# SKEAZN84 register map
Vendor: Freescale Semiconductor, Inc.; Series: Kinetis_EA; File version: 1.6
CPU: CM0PLUS r0p0, little endian, no MPU, no FPU, VTOR, 2 interrupt priority bits
Registers are 32-bit, read-write, reset 0x0 unless marked. A register's access mark holds for its fields unless they carry their own. Offsets are from the block's base; [hi:lo] are bit positions; {n}, {i} and the like mark numbered series; 'fields as' and 'values as' point back to an identical list.

## PORT — Port control and interrupts
Base 0x40049000; register names take the prefix PORT_
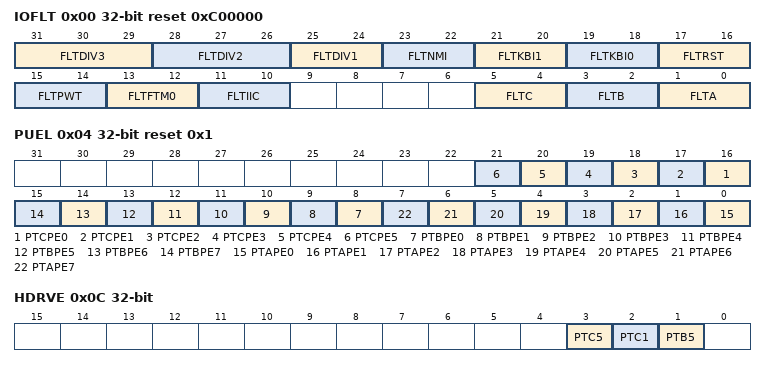
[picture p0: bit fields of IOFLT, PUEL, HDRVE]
0x00 IOFLT reset 0xC00000 — Port Filter Register
  [31:29] FLTDIV3 — Filter Division Set 3
    0=LPOCLK; 1=LPOCLK/2; 2=LPOCLK/4; 3=LPOCLK/8; 4=LPOCLK/16; 5=LPOCLK/32; 6=LPOCLK/64; 7=LPOCLK/128
  [28:26] FLTDIV2 — Filter Division Set 2
    0=BUSCLK/32; 1=BUSCLK/64; 2=BUSCLK/128; 3=BUSCLK/256; 4=BUSCLK/512; 5=BUSCLK/1024; 6=BUSCLK/2048; 7=BUSCLK/4096
  [25:24] FLTDIV1 — Filter Division Set 1
    0=BUSCLK/2; 1=BUSCLK/4; 2=BUSCLK/8; 3=BUSCLK/16
  [23:22] FLTNMI — Filter Selection for Input from NMI
    0=No filter; 1=Selects FLTDIV1, and will switch to FLTDIV3 in Stop mode automatically; 2=Selects FLTDIV2, and will switch to FLTDIV3 in Stop mode automatically; 3=FLTDIV3
  [21:20] FLTKBI1 — Filter Selection for Input from KBI1
    values as FLTNMI
  [19:18] FLTKBI0 — Filter selection for Input from KBI0
    values as FLTNMI
  [17:16] FLTRST — Filter Selection for Input from RESET/IRQ
    values as FLTNMI
  [15:14] FLTPWT — Filter Selection For Input from PWT_IN1/PWT_IN0
    0=No filter; 1=Select FLTDIV1; 2=Select FLTDIV2; 3=Select FLTDIV3
  [13:12] FLTFTM0 — Filter Selection For Input from FTM0CH0/FTM0CH1
    values as FLTPWT
  [11:10] FLTIIC — Filter Selection For Input from SCL/SDA
    0=No filter; 1=Select FLTDIV1; 2=Select FLTDIV2; 3=Select BUSCLK
  [5:4] FLTC — Filter Selection for Input from PTC
    0=BUSCLK; 1=FLTDIV1; 2=FLTDIV2; 3=FLTDIV3
  [3:2] FLTB — Filter Selection for Input from PTB
    0=BUSCLK; 1=FLTDIV1; 2=FLTDIV2; 3=FLTDIV3
  [1:0] FLTA — Filter Selection for Input from PTA
    0=BUSCLK; 1=FLTDIV1; 2=FLTDIV2; 3=FLTDIV3
0x04 PUEL reset 0x1 — Port Pullup Enable Low Register
  [n+16] PTCPE{n} (n=0..5) — Pull Enable for Port C Bit {n}
    0=Pullup is disabled for port C bit {n}; 1=Pullup is enabled for port C bit {n}
  [n+8] PTBPE{n} (n=0..7) — Pull Enable for Port B Bit {n}
    0=Pullup is disabled for port B bit {n}; 1=Pullup is enabled for port B bit {n}
  [n] PTAPE{n} (n=0..7) — Pull Enable for Port A Bit {n}
    0=Pullup is disabled for port A bit {n}; 1=Pullup is enabled for port A bit {n}
0x0C HDRVE — Port High Drive Enable Register
  [3] PTC5 — High Current Drive Capability of PTC5
    0=PTC5 is disabled to offer high current drive capability; 1=PTC5 is enabled to offer high current drive capability
  [2] PTC1 — High Current Drive Capability of PTC1
    0=PTC1 is disabled to offer high current drive capability; 1=PTC1 is enabled to offer high current drive capability
  [1] PTB5 — High Current Drive Capability of PTB5
    0=PTB5 is disabled to offer high current drive capability; 1=PTB5 is enabled to offer high current drive capability

## WDOG — Watchdog timer
Base 0x40052000; register names take the prefix WDOG_
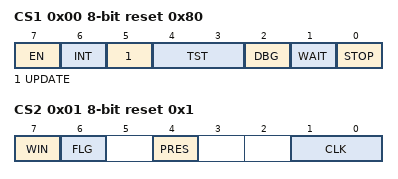
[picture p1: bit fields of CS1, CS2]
0x00 CS1 8-bit reset 0x80 — Watchdog Control and Status Register 1
  [7] EN — Watchdog Enable
    0=Watchdog disabled; 1=Watchdog enabled
  [6] INT — Watchdog Interrupt
    0=Watchdog interrupts are disabled. Watchdog resets are not delayed.; 1=Watchdog interrupts are enabled. Watchdog resets are delayed by 128 bus clocks.
  [5] UPDATE — Allow updates
    0=Updates not allowed. After the initial configuration, the watchdog cannot be later modified without forcing a reset.; 1=Updates allowed. Software can modify the watchdog configuration registers within 128 bus clocks after performing the unlock write sequence.
  [4:3] TST — Watchdog Test
    0=Watchdog test mode disabled; 1=Watchdog user mode enabled. (Watchdog test mode disabled.) After testing the watchdog, software should use this setting to indicate that the watchdog is functioning normally in user mode.; 2=Watchdog test mode enabled, only the low byte is used. WDOG_CNTL is compared with WDOG_TOVALL.; 3=Watchdog test mode enabled, only the high byte is used. WDOG_CNTH is compared with WDOG_TOVALH.
  [2] DBG — Debug Enable
    0=Watchdog disabled in chip debug mode; 1=Watchdog enabled in chip debug mode
  [1] WAIT — Wait Enable
    0=Watchdog disabled in chip wait mode; 1=Watchdog enabled in chip wait mode
  [0] STOP — Stop Enable
    0=Watchdog disabled in chip stop mode; 1=Watchdog enabled in chip stop mode
0x01 CS2 8-bit reset 0x1 — Watchdog Control and Status Register 2
  [7] WIN — Watchdog Window
    0=Window mode disabled; 1=Window mode enabled
  [6] FLG — Watchdog Interrupt Flag
    0=No interrupt occurred; 1=An interrupt occurred
  [4] PRES — Watchdog Prescalar
    0=256 prescalar disabled; 1=256 prescalar enabled
  [1:0] CLK — Watchdog Clock
    0=Bus clock; 1=1 kHz internal low-power oscillator (LPOCLK); 2=32 kHz internal oscillator (ICSIRCLK); 3=External clock source
0x02 CNT 16-bit (WDOG view) — Watchdog Counter Register.
  [15:0] CNT — Watchdog Counter Value
0x02 CNTH 8-bit ro (WDOG view) — Watchdog Counter Register: High
  [7:0] CNTHIGH — High byte of the Watchdog Counter
0x03 CNTL 8-bit ro — Watchdog Counter Register: Low
  [7:0] CNTLOW — Low byte of the Watchdog Counter
0x04 TOVAL 16-bit (WDOG view) — Watchdog Timeout Value Register.
  [15:0] TOVAL — Watchdog Timeout Value
0x04 TOVALH 8-bit (WDOG view) — Watchdog Timeout Value Register: High
  [7:0] TOVALHIGH — High byte of the timeout value
0x05 TOVALL 8-bit reset 0x4 — Watchdog Timeout Value Register: Low
  [7:0] TOVALLOW — Low byte of the timeout value
0x06 WIN 16-bit (WDOG view) — Watchdog Window Register.
  [15:0] WIN — Watchdog Window Value
0x06 WINH 8-bit (WDOG view) — Watchdog Window Register: High
  [7:0] WINHIGH — High byte of Watchdog Window
0x07 WINL 8-bit — Watchdog Window Register: Low
  [7:0] WINLOW — Low byte of Watchdog Window
